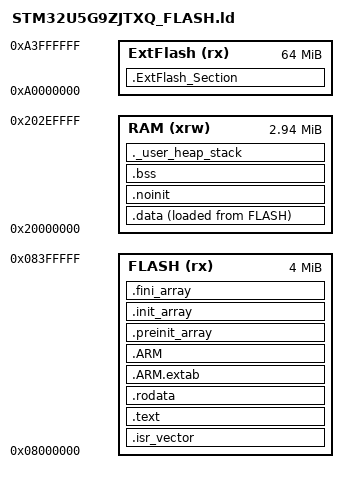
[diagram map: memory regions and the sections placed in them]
/*
******************************************************************************
**
** @file        : LinkerScript.ld
**
** @author      : Auto-generated by STM32CubeIDE
**
**  Abstract    : Linker script for STM32U5G9J-DK2 Board embedding STM32U5G9ZJTxQ Device from stm32u5 series
**                      4096KBytes FLASH
**                      3008KBytes RAM
**
**                Set heap size, stack size and stack location according
**                to application requirements.
**
**                Set memory bank area and size if external memory is used
**
**  Target      : STMicroelectronics STM32
**
**  Distribution: The file is distributed as is, without any warranty
**                of any kind.
**
******************************************************************************
** @attention
**
** Copyright (c) 2025 STMicroelectronics.
** All rights reserved.
**
** This software is licensed under terms that can be found in the LICENSE file
** in the root directory of this software component.
** If no LICENSE file comes with this software, it is provided AS-IS.
**
******************************************************************************
*/
/* Entry Point */
ENTRY(Reset_Handler)
/* Highest address of the user mode stack */
_estack = ORIGIN(RAM) + LENGTH(RAM); /* end of "RAM" Ram type memory */
_Min_Heap_Size = 0x200; /* required amount of heap */
_Min_Stack_Size = 0x400; /* required amount of stack */
/* Start user variables */

/* End user variables */

/* Memories definition */
MEMORY
{
/* Start MX regions */
  ExtFlash	(rx)	: ORIGIN = 0xa0000000, LENGTH = 65536K
  FLASH	(rx)	: ORIGIN = 0x08000000, LENGTH = 4096K
  RAM	(xrw)	: ORIGIN = 0x20000000, LENGTH = 3008K
/* End MX regions */
}
/* Sections */
SECTIONS
{
  /* The startup code into "FLASH" Rom type memory */
  .isr_vector :
  {
    . = ALIGN(4);
    KEEP(*(.isr_vector)) /* Startup code */
    . = ALIGN(4);
  } >FLASH
  /* The program code and other data into "FLASH" Rom type memory */
  .text :
  {
    . = ALIGN(4);
    *(.text)           /* .text sections (code) */
    *(.text*)          /* .text* sections (code) */
    *(.glue_7)         /* glue arm to thumb code */
    *(.glue_7t)        /* glue thumb to arm code */
    *(.eh_frame)
    KEEP (*(.init))
    KEEP (*(.fini))
    . = ALIGN(4);
    _etext = .;        /* define a global symbols at end of code */
  } >FLASH
  /* Constant data into "FLASH" Rom type memory */
  .rodata :
  {
    . = ALIGN(4);
    *(.rodata)         /* .rodata sections (constants, strings, etc.) */
    *(.rodata*)        /* .rodata* sections (constants, strings, etc.) */
    . = ALIGN(4);
  } >FLASH
  .ARM.extab (READONLY) : /* The "READONLY" keyword is only supported in GCC11 and later, remove it if using GCC10 or earlier. */
  {
    . = ALIGN(4);
    *(.ARM.extab* .gnu.linkonce.armextab.*)
    . = ALIGN(4);
  } >FLASH
  .ARM (READONLY) : /* The "READONLY" keyword is only supported in GCC11 and later, remove it if using GCC10 or earlier. */
  {
    . = ALIGN(4);
    __exidx_start = .;
    *(.ARM.exidx*)
    __exidx_end = .;
    . = ALIGN(4);
  } >FLASH
  .preinit_array (READONLY) : /* The "READONLY" keyword is only supported in GCC11 and later, remove it if using GCC10 or earlier. */
  {
    . = ALIGN(4);
    PROVIDE_HIDDEN (__preinit_array_start = .);
    KEEP (*(.preinit_array*))
    PROVIDE_HIDDEN (__preinit_array_end = .);
    . = ALIGN(4);
  } >FLASH
  .init_array (READONLY) : /* The "READONLY" keyword is only supported in GCC11 and later, remove it if using GCC10 or earlier. */
  {
    . = ALIGN(4);
    PROVIDE_HIDDEN (__init_array_start = .);
    KEEP (*(SORT(.init_array.*)))
    KEEP (*(.init_array*))
    PROVIDE_HIDDEN (__init_array_end = .);
    . = ALIGN(4);
  } >FLASH
  .fini_array (READONLY) : /* The "READONLY" keyword is only supported in GCC11 and later, remove it if using GCC10 or earlier. */
  {
    . = ALIGN(4);
    PROVIDE_HIDDEN (__fini_array_start = .);
    KEEP (*(SORT(.fini_array.*)))
    KEEP (*(.fini_array*))
    PROVIDE_HIDDEN (__fini_array_end = .);
    . = ALIGN(4);
  } >FLASH
  /* Used by the startup to initialize data */
  _sidata = LOADADDR(.data);
  /* Initialized data sections into "RAM" Ram type memory */
  .data :
  {
    . = ALIGN(4);
    _sdata = .;        /* create a global symbol at data start */
    *(.data)           /* .data sections */
    *(.data*)          /* .data* sections */
    *(.RamFunc)        /* .RamFunc sections */
    *(.RamFunc*)       /* .RamFunc* sections */
    . = ALIGN(4);
    _edata = .;        /* define a global symbol at data end */
  } >RAM AT> FLASH
  /* Uninitialized data section into "RAM" Ram type memory */
  . = ALIGN(4);
  
  .noinit (NOLOAD) :
  {
    . = ALIGN(4);
    *(.noinit)
    . = ALIGN(4);
  } > RAM
  
  .bss :
  {
    /* This is used by the startup in order to initialize the .bss section */
    _sbss = .;         /* define a global symbol at bss start */
    __bss_start__ = _sbss;
    *(.bss)
    *(.bss*)
    *(COMMON)
    . = ALIGN(4);
    _ebss = .;         /* define a global symbol at bss end */
    __bss_end__ = _ebss;
  } >RAM
  /* User_heap_stack section, used to check that there is enough "RAM" Ram  type memory left */
  ._user_heap_stack :
  {
    . = ALIGN(8);
    PROVIDE ( end = . );
    PROVIDE ( _end = . );
    . = . + _Min_Heap_Size;
    . = . + _Min_Stack_Size;
    . = ALIGN(8);
  } >RAM
  /* Remove information from the compiler libraries */
  /DISCARD/ :
  {
    libc.a ( * )
    libm.a ( * )
    libgcc.a ( * )
  }
  .ARM.attributes 0 : { *(.ARM.attributes) }
 /*  Unitialized ExtFlash section into "ExtFlash" ExtFlash type memory [MMT section] */
 .ExtFlash_Section (NOLOAD) :
  {
    . = ALIGN(4);
    KEEP (*(.ExtFlash_Section))
    . = ALIGN(4);
  } >ExtFlash
}
